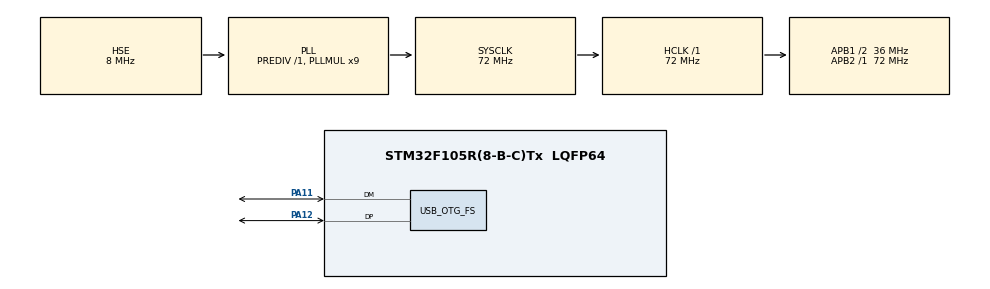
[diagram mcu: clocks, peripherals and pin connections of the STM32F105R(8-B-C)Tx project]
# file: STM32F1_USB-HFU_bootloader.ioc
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FATFS._FS_LOCK=0
FATFS._FS_MINIMIZE=0
FATFS._FS_READONLY=0
FATFS._USE_FASTSEEK=0
FATFS._USE_LFN=1
FATFS._USE_MKFS=0
FATFS._USE_STRFUNC=0
Mcu.Family=STM32F1
Mcu.Name=STM32F105R(8-B-C)Tx
Mcu.Package=LQFP64
NVIC.OTG_FS_IRQn=true\:0\:0\:false\:false\:true\:false\:true\:true
NVIC.PriorityGroup=NVIC_PRIORITYGROUP_4
PA11.Mode=Host_Only
PA11.Signal=USB_OTG_FS_DM
PA12.Mode=Host_Only
PA12.Signal=USB_OTG_FS_DP
PA13.Mode=Serial_Wire
PA13.Signal=SYS_JTMS-SWDIO
PA14.Mode=Serial_Wire
PA14.Signal=SYS_JTCK-SWCLK
PD0-OSC_IN.Mode=HSE-External-Oscillator
PD0-OSC_IN.Signal=RCC_OSC_IN
PD1-OSC_OUT.Mode=HSE-External-Oscillator
PD1-OSC_OUT.Signal=RCC_OSC_OUT
ProjectManager.HeapSize=0x200
ProjectManager.StackSize=0x400
ProjectManager.TargetToolchain=STM32CubeIDE
RCC.AHBFreq_Value=72000000
RCC.APB1CLKDivider=RCC_HCLK_DIV2
RCC.APB1Freq_Value=36000000
RCC.APB1TimFreq_Value=72000000
RCC.APB2Freq_Value=72000000
RCC.APB2TimFreq_Value=72000000
RCC.HCLKFreq_Value=72000000
RCC.PLLMUL=RCC_PLL_MUL9
RCC.SYSCLKFreq_VALUE=72000000
RCC.SYSCLKSource=RCC_SYSCLKSOURCE_PLLCLK
RCC.USBFreq_Value=48000000
USB_HOST.USBH_HandleTypeDef=hUsbHostFS
USB_HOST.VirtualModeFS=Msc
USB_OTG_FS.VirtualMode=Host_Only
VP_CRC_VS_CRC.Mode=CRC_Activate
VP_FATFS_VS_USB.Mode=USB
VP_USB_HOST_VS_USB_HOST_MSC_FS.Mode=MSC_FS
board=custom

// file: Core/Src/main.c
/* USER CODE BEGIN Header */
/**
  ******************************************************************************
  * @file           : main.c
  * @brief          : Main program body
  ******************************************************************************
  * @attention
  *
  * Copyright (c) 2023 STMicroelectronics.
  * All rights reserved.
  *
  * This software is licensed under terms that can be found in the LICENSE file
  * in the root directory of this software component.
  * If no LICENSE file comes with this software, it is provided AS-IS.
  *
  ******************************************************************************
  */
/* USER CODE END Header */
#include "main.h"
#include "fatfs.h"
#include "usb_host.h"

/* USER CODE BEGIN Includes */
#include "command.h"

/* USER CODE END Includes */

CRC_HandleTypeDef hcrc;

void SystemClock_Config(void);
static void MX_GPIO_Init(void);
static void MX_CRC_Init(void);
void MX_USB_HOST_Process(void);

int main(void)
{

  /* MCU Configuration--------------------------------------------------------*/

  /* Reset of all peripherals, Initializes the Flash interface and the Systick. */
  HAL_Init();

  /* Configure the system clock */
  SystemClock_Config();

  /* Initialize all configured peripherals */
  MX_GPIO_Init();
  MX_FATFS_Init();
  MX_USB_HOST_Init();
  MX_CRC_Init();

  /* Infinite loop */
  /* USER CODE BEGIN WHILE */
  diskprocess=0; //0=disk absent ; 1=disk inserted ; 2=disk processed
  cyclesCount=0;
  app_flashed=0;
  app_detected=DETECT_APP(); //Check that vector table of application is within range
  uint8_t cont=1;

  while (cont)
  {
    /* USER CODE END WHILE */
    MX_USB_HOST_Process();

    /* USER CODE BEGIN 3 */
    if(diskprocess==1){
    	COMMAND_UPDATE();
    	app_detected=DETECT_APP();
    	diskprocess++;
    }
    cont=(!app_detected) | ((cyclesCount++ < WAIT_CYCLES) & (diskprocess < 2)); //stay in bootloader if no app present or leave when an inserted disk has been processed or after a timeout for mass storage to come up
  }
  COMMAND_JUMP();

  /* USER CODE END 3 */
}

void SystemClock_Config(void)
{
  RCC_OscInitTypeDef RCC_OscInitStruct = {0};
  RCC_ClkInitTypeDef RCC_ClkInitStruct = {0};
  RCC_PeriphCLKInitTypeDef PeriphClkInit = {0};

  /** Initializes the RCC Oscillators according to the specified parameters
  * in the RCC_OscInitTypeDef structure.
  */
  RCC_OscInitStruct.OscillatorType = RCC_OSCILLATORTYPE_HSE;
  RCC_OscInitStruct.HSEState = RCC_HSE_ON;
  RCC_OscInitStruct.HSEPredivValue = RCC_HSE_PREDIV_DIV1;
  RCC_OscInitStruct.HSIState = RCC_HSI_ON;
  RCC_OscInitStruct.Prediv1Source = RCC_PREDIV1_SOURCE_HSE;
  RCC_OscInitStruct.PLL.PLLState = RCC_PLL_ON;
  RCC_OscInitStruct.PLL.PLLSource = RCC_PLLSOURCE_HSE;
  RCC_OscInitStruct.PLL.PLLMUL = RCC_PLL_MUL9;
  RCC_OscInitStruct.PLL2.PLL2State = RCC_PLL_NONE;
  if (HAL_RCC_OscConfig(&RCC_OscInitStruct) != HAL_OK)
  {
    Error_Handler();
  }

  /** Initializes the CPU, AHB and APB buses clocks
  */
  RCC_ClkInitStruct.ClockType = RCC_CLOCKTYPE_HCLK|RCC_CLOCKTYPE_SYSCLK
                              |RCC_CLOCKTYPE_PCLK1|RCC_CLOCKTYPE_PCLK2;
  RCC_ClkInitStruct.SYSCLKSource = RCC_SYSCLKSOURCE_PLLCLK;
  RCC_ClkInitStruct.AHBCLKDivider = RCC_SYSCLK_DIV1;
  RCC_ClkInitStruct.APB1CLKDivider = RCC_HCLK_DIV2;
  RCC_ClkInitStruct.APB2CLKDivider = RCC_HCLK_DIV1;

  if (HAL_RCC_ClockConfig(&RCC_ClkInitStruct, FLASH_LATENCY_2) != HAL_OK)
  {
    Error_Handler();
  }
  PeriphClkInit.PeriphClockSelection = RCC_PERIPHCLK_USB;
  PeriphClkInit.UsbClockSelection = RCC_USBCLKSOURCE_PLL_DIV3;
  if (HAL_RCCEx_PeriphCLKConfig(&PeriphClkInit) != HAL_OK)
  {
    Error_Handler();
  }

  /** Configure the Systick interrupt time
  */
  __HAL_RCC_PLLI2S_ENABLE();
}

static void MX_CRC_Init(void)
{

  hcrc.Instance = CRC;
  if (HAL_CRC_Init(&hcrc) != HAL_OK)
  {
    Error_Handler();
  }

}

static void MX_GPIO_Init(void)
{

  /* GPIO Ports Clock Enable */
  __HAL_RCC_GPIOD_CLK_ENABLE();
  __HAL_RCC_GPIOA_CLK_ENABLE();

}

void Error_Handler(void)
{
  __disable_irq();
  while (1)
  {
  }
}
